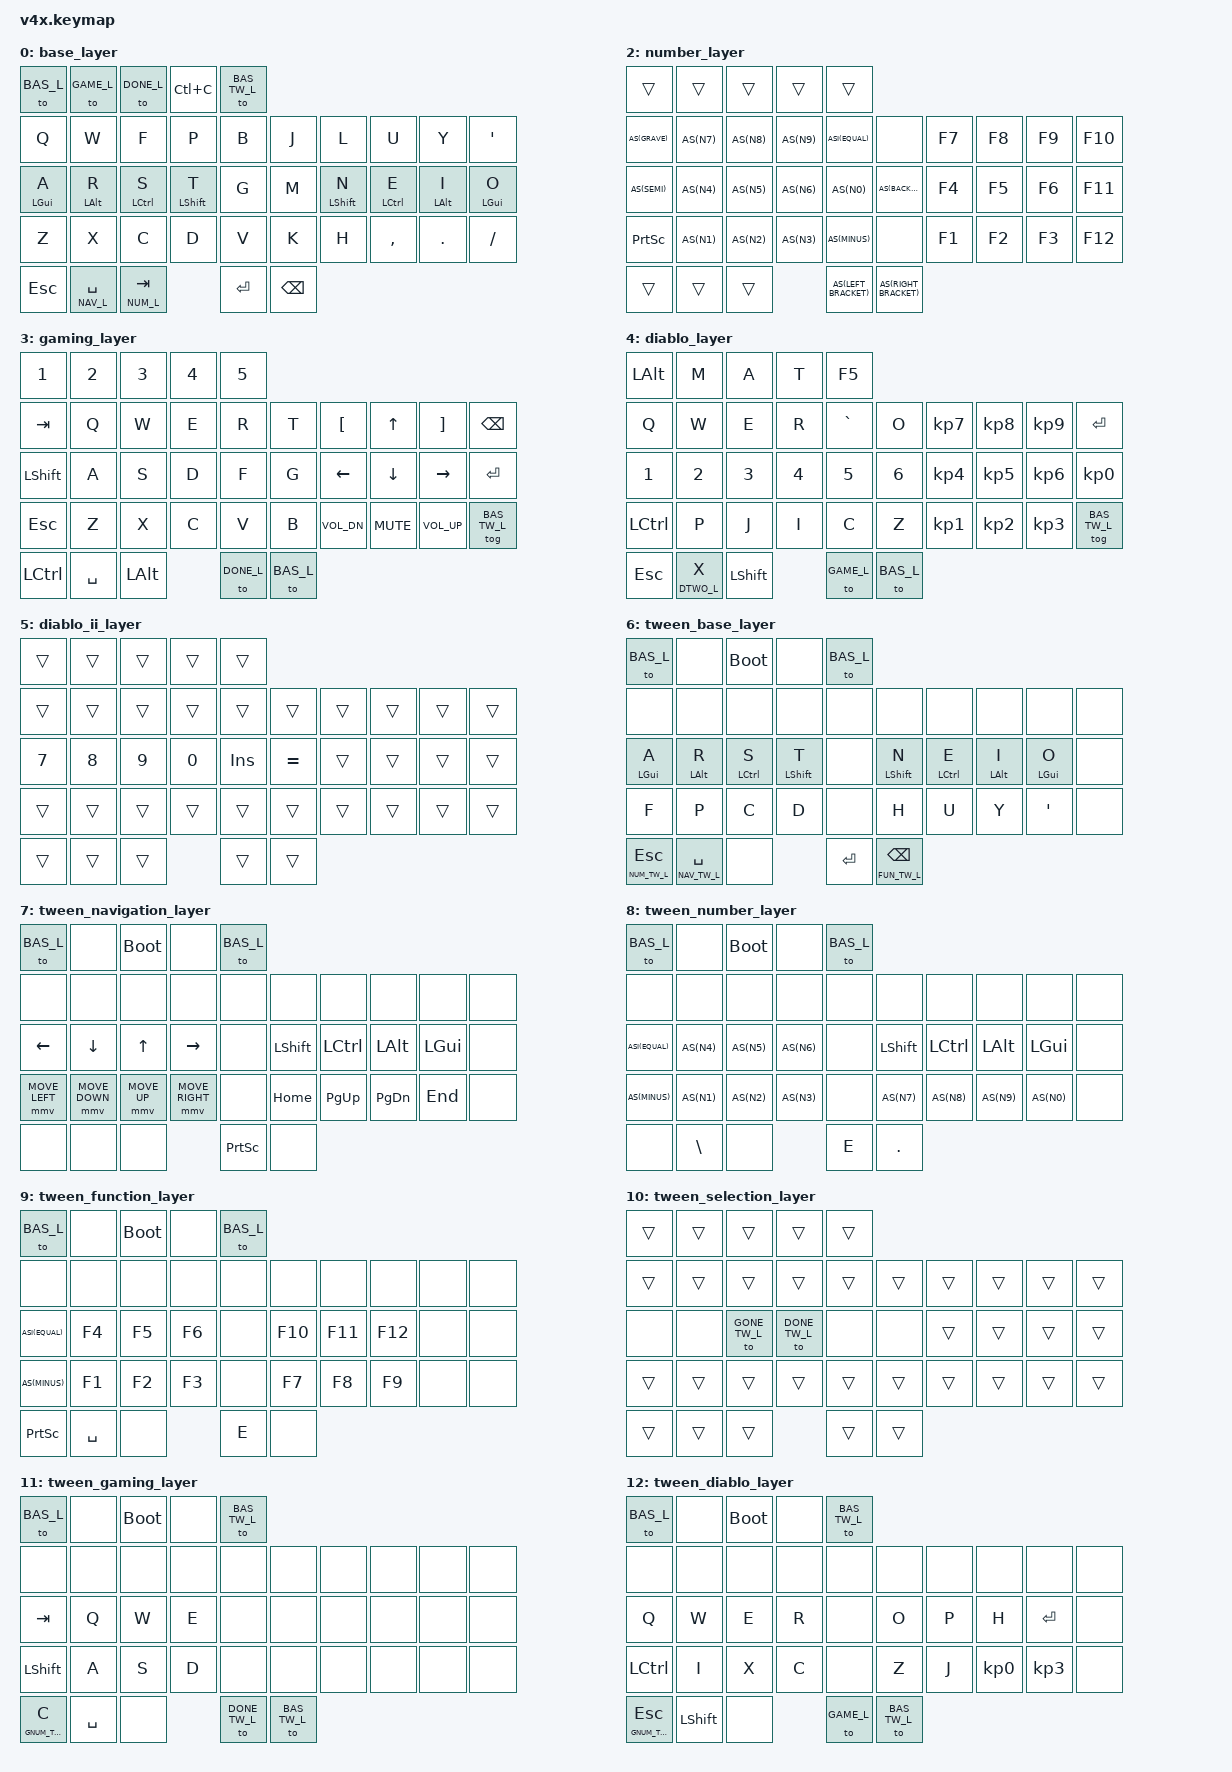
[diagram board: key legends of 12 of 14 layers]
/*
 * Copyright (c) 2024 Rooks
 *
 * SPDX-License-Identifier: MIT
 */

#include <behaviors.dtsi>
#include <dt-bindings/zmk/keys.h>
#include <dt-bindings/zmk/mouse.h>
#include <dt-bindings/zmk/bt.h>
#include <dt-bindings/zmk/outputs.h>

#define AS(keycode) &as LS(keycode) keycode     // Autoshift Macro
#define ASI(keycode) &as keycode LS(keycode)     // Autoshift Macro inverted
#define BAS_L 0
#define NAV_L 1
#define NUM_L 2
#define GAME_L 3
#define DONE_L 4
#define DTWO_L 5
#define BAS_TW_L 6
#define NAV_TW_L 7
#define NUM_TW_L 8
#define FUN_TW_L 9
#define SEL_TW_L 10
#define GONE_TW_L 11
#define DONE_TW_L 12
#define GNUM_TW_L 13


/*  0  1  2  3   4
 *  5  6  7  8   9  10 11 12 13  14
 * 15 16 17 18  19  20 21 22 23  24
 * 25 26 27 28  29  30 32 32 33  34
 *       35 36  37  38 39
 */



#define KEYS_L 5  6  7  8  9   15 16 17 18 19  25 26 27 28 29
#define KEYS_R 10 11 12 13 14  20 21 22 23 24  30 31 32 33 34

#define THUMBS 35 36 37 38 39

// Using layer taps on thumbs, having quick tap as well helps w/ repeating space/backspace
&lt { quick_tap_ms = <200>; };

#define BT(n) BT_SEL n

/ {
    behaviors {
        hml: hrm_left {
            compatible = "zmk,behavior-hold-tap";
            #binding-cells = <2>;
            bindings = <&kp>, <&kp>;
            flavor = "balanced";
            tapping-term-ms = <200>;
            quick-tap-ms = <150>;
            hold-trigger-key-positions = <KEYS_R THUMBS>;
            hold-trigger-on-release;
        };
        hmr: hrm_right {
            compatible = "zmk,behavior-hold-tap";
            #binding-cells = <2>;
            bindings = <&kp>, <&kp>;
            flavor = "balanced";
            tapping-term-ms = <200>;
            quick-tap-ms = <150>;
            hold-trigger-key-positions = <KEYS_L THUMBS>;
            hold-trigger-on-release;
        };
        as: auto_shift {
            compatible = "zmk,behavior-hold-tap";
            #binding-cells = <2>;
            bindings = <&kp>, <&kp>;
            flavor = "tap-preferred";
            tapping_term_ms = <200>;
            quick_tap_ms = <100>;
        };
        ght: gamers_hold_tap {
            compatible = "zmk,behavior-hold-tap";
            #binding-cells = <2>;
            bindings = <&kp>, <&kp>;
            flavor = "hold-preferred";
            tapping_term_ms = <150>;
        };
        fshr: f_shift_r {
            compatible = "zmk,behavior-mod-morph";
            #binding-cells = <0>;
            bindings = <&kp F>, <&kp R>;
            mods = <(MOD_LSFT)>;
            keep-mods = <(MOD_LSFT)>;
        };

    };

    keymap {
        compatible = "zmk,keymap";

        base_layer {
            bindings = <
                       &to BAS_L    &to GAME_L &to DONE_L &kp LC(C) &to BAS_TW_L
                &kp Q         &kp W         &kp F          &kp P           &kp B       &kp J      &kp L          &kp U          &kp Y         &kp QUOT
                &hml LGUI A   &hml LALT R   &hml LCTRL S   &hml LSHFT T    &kp G       &kp M      &hmr LSHFT N   &hmr LCTRL E   &hmr LALT I   &hmr LGUI O
                &kp Z         &kp X         &kp C          &kp D           &kp V       &kp K      &kp H          &kp COMMA      &kp DOT       &kp FSLH
                &kp ESC        &lt NAV_L SPACE &lt NUM_L TAB        &kp RET    &kp BKSP
                >;
        };
        navigate_layer {
            bindings = <
                &trans &bt BT(0) &bt BT(1) &kp C_VOL_DN &kp C_VOL_UP
                &mmv MOVE_LEFT &mmv MOVE_DOWN &mmv MOVE_UP &mmv MOVE_RIGHT &kp HOME     &kp PG_UP    &kp C_MUTE  &kp C_VOL_DN &kp C_VOL_UP &none
                &kp LEFT       &kp DOWN       &kp UP       &kp RIGHT       &out OUT_USB &out OUT_BLE &kp LSHFT &kp LCTRL    &kp LALT     &kp LGUI
                &msc SCRL_LEFT &msc SCRL_DOWN &msc SCRL_UP &msc SCRL_RIGHT &kp END      &kp PG_DN    &caps_word &bt BT(0)    &bt BT(1)    &bt BT(2)
                                              &trans       &trans          &mkp LCLK &mkp MCLK &mkp RCLK
                >;
        };

        number_layer {
            bindings = <
                &trans &trans &trans &trans &trans
                AS(GRAVE) AS(N7) AS(N8) AS(N9) ASI(EQUAL) &none &kp F7 &kp F8 &kp F9 &kp F10
                AS(SEMI)  AS(N4) AS(N5) AS(N6) AS(N0)     AS(BACKSLASH) &kp F4 &kp F5 &kp F6 &kp F11
                &kp PSCRN AS(N1) AS(N2) AS(N3) AS(MINUS)  &none &kp F1 &kp F2 &kp F3 &kp F12
                    &trans &trans &trans AS(LEFT_BRACKET) AS(RIGHT_BRACKET)
                >;
        };

        gaming_layer {
            bindings = <
                &kp N1 &kp N2 &kp N3 &kp N4 &kp N5
                &kp TAB    &kp Q &kp W &kp E &kp R &kp T &kp LEFT_BRACKET &kp UP   &kp RIGHT_BRACKET &kp BACKSPACE
                &kp LSHIFT &kp A &kp S &kp D &kp F &kp G &kp LEFT         &kp DOWN &kp RIGHT         &kp RETURN
                &kp ESC    &kp Z &kp X &kp C &kp V &kp B &kp C_VOL_DN &kp C_MUTE &kp C_VOL_UP &tog BAS_TW_L
                &kp LCTRL &kp SPACE &kp LALT &to DONE_L &to BAS_L
                >;
        };

        diablo_layer {
            bindings = <
                &kp LALT &kp M &kp A &kp T &kp F5
                &kp Q &kp W &kp E &kp R &kp GRAVE &kp O &kp KP_N7 &kp KP_N8 &kp KP_N9 &kp RETURN
                &kp N1 &kp N2 &kp N3 &kp N4 &kp N5 &kp N6 &kp KP_N4 &kp KP_N5 &kp KP_N6 &kp KP_N0
                &kp LCTRL &kp P &kp J &kp I &kp C &kp Z &kp KP_N1 &kp KP_N2 &kp KP_N3 &tog BAS_TW_L
                &kp ESC &lt DTWO_L X &kp LSHIFT &to GAME_L &to BAS_L
                >;
        };

        diablo_ii_layer {
            bindings = <
                &trans &trans &trans &trans &trans
                &trans &trans &trans &trans &trans &trans &trans &trans &trans &trans
                &kp N7 &kp N8 &kp N9 &kp N0 &kp INS &kp EQUAL &trans &trans &trans &trans
                &trans &trans &trans &trans &trans &trans &trans &trans &trans &trans
                &trans &trans &trans &trans &trans
                >;
        };

        tween_base_layer {
            bindings = <
                &to BAS_L &none &bootloader &none &to BAS_L
                &none &none &none &none &none &none &none &none &none &none
                &hml LGUI A &hml LALT R &hml LCTRL S &hml LSHFT T    &none    &hmr LSHFT N   &hmr LCTRL E   &hmr LALT I   &hmr LGUI O  &none
                &kp F   &kp P       &kp C        &kp D           &none    &kp H          &kp U          &kp Y         &kp QUOT     &none
                &lt NUM_TW_L ESC &lt NAV_TW_L SPACE &none &kp RET &lt FUN_TW_L BKSP
                >;
        };

        tween_navigation_layer {
            bindings = <
                &to BAS_L &none &bootloader &none &to BAS_L
                &none &none &none &none &none &none &none &none &none &none
                 &kp LEFT       &kp DOWN       &kp UP       &kp RIGHT      &none &kp LSHFT &kp LCTRL &kp LALT &kp LGUI &none
                &mmv MOVE_LEFT &mmv MOVE_DOWN &mmv MOVE_UP &mmv MOVE_RIGHT &none &kp HOME  &kp PG_UP &kp PG_DN &kp END &none
                &none &none &none &kp PSCRN &none
                >;
        };

        tween_number_layer {
            bindings = <
                &to BAS_L &none &bootloader &none &to BAS_L
                &none &none &none &none &none &none &none &none &none &none
                ASI(EQUAL) AS(N4) AS(N5) AS(N6) &none &kp LSHFT &kp LCTRL &kp LALT &kp LGUI &none
                 AS(MINUS) AS(N1) AS(N2) AS(N3) &none  AS(N7)    AS(N8)    AS(N9)   AS(N0) &none
                &none &kp BACKSLASH &none &kp E &kp DOT
                >;
        };

        tween_function_layer {
            bindings = <
                &to BAS_L &none &bootloader &none &to BAS_L
                &none &none &none &none &none &none &none &none &none &none
                ASI(EQUAL) &kp F4 &kp F5 &kp F6 &none &kp F10 &kp F11 &kp F12 &none &none
                 AS(MINUS) &kp F1 &kp F2 &kp F3 &none &kp F7  &kp F8  &kp F9  &none &none
                &kp PSCRN &kp SPACE &none &kp E &none
                >;
        };

        tween_selection_layer {
            bindings = <
                &trans &trans &trans &trans &trans
                &trans &trans &trans &trans &trans &trans &trans &trans &trans &trans
                &none  &none  &to GONE_TW_L  &to DONE_TW_L  &none  &none  &trans &trans &trans &trans
                &trans &trans &trans &trans &trans &trans &trans &trans &trans &trans
                &trans &trans &trans &trans &trans
                >;
        };

        tween_gaming_layer {
            bindings = <
                &to BAS_L &none &bootloader &none &to BAS_TW_L
                &none &none &none &none &none &none &none &none &none &none
                &kp TAB &kp Q &kp W &kp E &none &none &none &none &none &none
                &kp LSHFT &kp A &kp S &kp D &none &none &none &none &none &none
                &lt GNUM_TW_L C &kp SPACE &none &to DONE_TW_L &to BAS_TW_L
                >;
        };

        tween_diablo_layer {
            bindings = <
                &to BAS_L &none &bootloader &none &to BAS_TW_L
                &none &none &none &none &none &none &none &none &none &none
                &kp Q &kp W &kp E &kp R &none &kp O &kp P &kp H &kp RET &none
                &kp LCTRL &kp I &kp X &kp C &none &kp Z &kp J &kp KP_N0 &kp KP_N3   &none
                &lt GNUM_TW_L ESC &kp LSHFT &none &to GAME_L &to BAS_TW_L
                >;
            // IWC
        };

        tween_gaming_number_layer {
            bindings = <
                &trans &trans &trans &trans &trans
                &trans &trans &trans &trans &trans &trans &trans &trans &trans &trans
                &kp N1 &kp N2 &kp N3 &kp N4 &none                     &none &none &none &trans &trans
                &ght N9 N5 &ght N0 N6 &ght EQUAL N7 &ght INS N8 &none &none &none &none &none   &none
                &trans &kp GRAVE &trans &trans &trans
                >;
        };

    };

    combos {
        compatible = "zmk,combos";
        combo_boot { timeout-ms = <50>; key-positions = <5 14 25 34>; bindings = <&bootloader>; };
        combo_del { timeout-ms = <50>; key-positions = <34 39>; bindings = <&kp DEL>; layers = <BAS_L>; };

        combo_tw_w         { timeout-ms = <50>; key-positions = <15 16>; bindings = <&kp W>; layers = <BAS_TW_L>; };
        combo_tw_g         { timeout-ms = <50>; key-positions = <16 17>; bindings = <&kp G>; layers = <BAS_TW_L GONE_TW_L>; };
        combo_tw_b         { timeout-ms = <50>; key-positions = <17 18>; bindings = <&kp B>; layers = <BAS_TW_L GONE_TW_L>; };
        combo_tw_j         { timeout-ms = <50>; key-positions = <20 21>; bindings = <&kp J>; layers = <BAS_TW_L>; };
        combo_tw_l         { timeout-ms = <50>; key-positions = <21 22>; bindings = <&kp L>; layers = <BAS_TW_L>; };
        combo_tw_m         { timeout-ms = <50>; key-positions = <22 23>; bindings = <&kp M>; layers = <BAS_TW_L>; };

        combo_tw_z         { timeout-ms = <50>; key-positions = <26 27>; bindings = <&kp Z>; layers = <BAS_TW_L GONE_TW_L>; };
        combo_tw_x         { timeout-ms = <50>; key-positions = <27 28>; bindings = <&kp X>; layers = <BAS_TW_L GONE_TW_L>; };
        combo_tw_comma     { timeout-ms = <50>; key-positions = <30 31>; bindings = <&kp COMMA>; layers = <BAS_TW_L>; };
        combo_tw_dot       { timeout-ms = <50>; key-positions = <31 32>; bindings = <&kp DOT>; layers = <BAS_TW_L>; };

        combo_tw_paren_l   { timeout-ms = <50>; key-positions = <18 28>; bindings = <&kp LPAR>; layers = <BAS_TW_L>; };
        combo_tw_paren_r   { timeout-ms = <50>; key-positions = <20 30>; bindings = <&kp RPAR>; layers = <BAS_TW_L>; };
        combo_tw_bracket_l { timeout-ms = <50>; key-positions = <17 27>; bindings = <&kp LBKT>; layers = <BAS_TW_L>; };
        combo_tw_bracket_r { timeout-ms = <50>; key-positions = <21 31>; bindings = <&kp RBKT>; layers = <BAS_TW_L>; };
        combo_tw_brace_l   { timeout-ms = <50>; key-positions = <16 26>; bindings = <&kp LBRC>; layers = <BAS_TW_L>; };
        combo_tw_brace_r   { timeout-ms = <50>; key-positions = <22 32>; bindings = <&kp RBRC>; layers = <BAS_TW_L>; };
        combo_tw_angle_l   { timeout-ms = <50>; key-positions = <16 28>; bindings = <&kp LT>; layers = <BAS_TW_L>; };
        combo_tw_angle_r   { timeout-ms = <50>; key-positions = <22 30>; bindings = <&kp GT>; layers = <BAS_TW_L>; };

        combo_tw_k         { timeout-ms = <50>; key-positions = <21 30>; bindings = <&kp K>; layers = <BAS_TW_L>; };
        combo_tw_v         { timeout-ms = <50>; key-positions = <17 28>; bindings = <&kp V>; layers = <BAS_TW_L GONE_TW_L>; };
        combo_tw_grave     { timeout-ms = <50>; key-positions = <16 27>; bindings = <&kp GRAVE>; layers = <BAS_TW_L>; };
        combo_tw_slash     { timeout-ms = <50>; key-positions = <22 31>; bindings = <&kp FSLH>; layers = <BAS_TW_L>; };

        combo_tw_q         { timeout-ms = <50>; key-positions = <26 28>; bindings = <&kp Q>; layers = <BAS_TW_L>; };
        combo_tw_tab       { timeout-ms = <50>; key-positions = <16 18>; bindings = <&kp TAB>; layers = <BAS_TW_L>; };

        combo_tw_esc       { timeout-ms = <50>; key-positions = <15 18>; bindings = <&kp ESC>; layers = <BAS_TW_L>; };
        combo_tw_capslock  { timeout-ms = <50>; key-positions = <16 22>; bindings = <&kp CAPS>; layers = <BAS_TW_L>; };
        combo_tw_capsword  { timeout-ms = <50>; key-positions = <18 20>; bindings = <&caps_word>; layers = <BAS_TW_L>; };
        combo_tw_delete    { timeout-ms = <50>; key-positions = <20 22>; bindings = <&kp DEL>; layers = <BAS_TW_L>; };
        combo_tw_back_word { timeout-ms = <50>; key-positions = <20 23>; bindings = <&kp LC(BKSP)>; layers = <BAS_TW_L>; };
        combo_tw_semicolon { timeout-ms = <50>; key-positions = <30 32>; bindings = <&kp SEMI>; layers = <BAS_TW_L>; };
        combo_tw_layer     { timeout-ms = <50>; key-positions = <38 39>; bindings = <&mo SEL_TW_L>; layers = <BAS_TW_L>; };

        combo_tw_game_esc  { timeout-ms = <50>; key-positions = <15 16>; bindings = <&kp ESC>; layers = <GONE_TW_L>; };
        combo_tw_game_lctl { timeout-ms = <50>; key-positions = <35 36>; bindings = <&kp LCTRL>; layers = <GONE_TW_L>; };
        combo_tw_game_lalt { timeout-ms = <50>; key-positions = <28 36>; bindings = <&kp LALT>; layers = <GONE_TW_L>; };
        combo_tw_game_fshr { timeout-ms = <50>; key-positions = <18 28>; bindings = <&fshr>; layers = <GONE_TW_L>; };
//        combo_tw_d2_pot1   { timeout-ms = <50>; key-positions = <15 25>; bindings = <&kp Q>; layers = <DONE_TW_L>; };
//        combo_tw_d2_pot2   { timeout-ms = <50>; key-positions = <16 26>; bindings = <&kp W>; layers = <DONE_TW_L>; };
//        combo_tw_d2_pot3   { timeout-ms = <50>; key-positions = <17 27>; bindings = <&kp E>; layers = <DONE_TW_L>; };
//        combo_tw_d2_pot4   { timeout-ms = <50>; key-positions = <18 28>; bindings = <&kp R>; layers = <DONE_TW_L>; };
    };

/*  0  1  2  3   4
 *  5  6  7  8   9  10 11 12 13  14
 * 15 16 17 18  19  20 21 22 23  24
 * 25 26 27 28  29  30 31 32 33  34
 *       35 36  37  38 39
 */

};

// vim: ft=c
